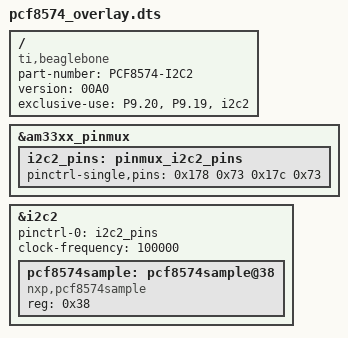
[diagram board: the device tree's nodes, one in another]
// in order to run put dtbo file into /lib/firmware and load it with capemanager

/dts-v1/;
/plugin/;

/ {
	compatible = "ti,beaglebone", "ti,beaglebone-black";

	/* identification */
	part-number = "PCF8574-I2C2";
	version = "00A0";

	/* state the resources this cape uses */
	exclusive-use = "P9.20", "P9.19", "i2c2"; /* i2c2_sda, i2c2_scl, ip uses */

	fragment@0 {
		target = <&am33xx_pinmux>;
		__overlay__ {
			i2c2_pins: pinmux_i2c2_pins {
				pinctrl-single,pins = <
					0x178 0x73 // spi0_d1.i2c2_sda,  SLEWCTRL_SLOW | IMPUT_PULLUP | MODE3
					0x17c 0x73 // spi0_cs0.i2c2_scl, SLEWCTRL_SLOW | INPUT_PULLUP | MODE3
				>;
			};
		};
	};

	fragment@1 {
		target = <&i2c2>;    /* i2c2 is numbered correctly */
		__overlay__ {
			status = "okay";
			pinctrl-names = "default";
			pinctrl-0 = <&i2c2_pins>;

			/* this is the configuration part */
			clock-frequency = <100000>;

			#address-cells = <1>;
			#size-cells = <0>;

			pcf8574sample: pcf8574sample@38 {
				compatible = "nxp,pcf8574sample";
				#address-cells = <1>;
				#size-cells = <0>;
				reg = <0x38>;
			};
		};
	};
};
